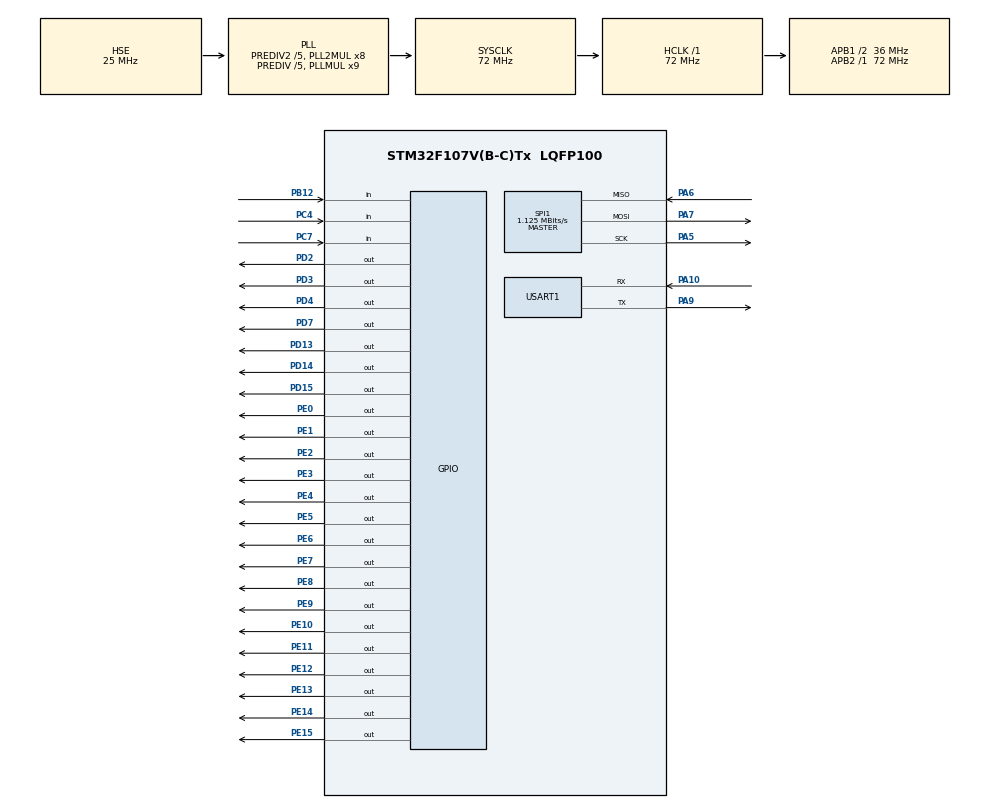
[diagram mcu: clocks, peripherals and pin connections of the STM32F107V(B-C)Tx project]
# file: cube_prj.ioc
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Dma.Request0=USART1_RX
Dma.Request1=USART1_TX
Dma.USART1_RX.0.Direction=DMA_PERIPH_TO_MEMORY
Dma.USART1_RX.0.Instance=DMA1_Channel5
Dma.USART1_RX.0.MemDataAlignment=DMA_MDATAALIGN_BYTE
Dma.USART1_RX.0.MemInc=DMA_MINC_DISABLE
Dma.USART1_RX.0.Mode=DMA_CIRCULAR
Dma.USART1_RX.0.PeriphDataAlignment=DMA_PDATAALIGN_BYTE
Dma.USART1_RX.0.PeriphInc=DMA_PINC_DISABLE
Dma.USART1_RX.0.Priority=DMA_PRIORITY_MEDIUM
Dma.USART1_TX.1.Direction=DMA_MEMORY_TO_PERIPH
Dma.USART1_TX.1.Instance=DMA1_Channel4
Dma.USART1_TX.1.MemDataAlignment=DMA_MDATAALIGN_BYTE
Dma.USART1_TX.1.MemInc=DMA_MINC_ENABLE
Dma.USART1_TX.1.Mode=DMA_NORMAL
Dma.USART1_TX.1.PeriphDataAlignment=DMA_PDATAALIGN_BYTE
Dma.USART1_TX.1.PeriphInc=DMA_PINC_DISABLE
Dma.USART1_TX.1.Priority=DMA_PRIORITY_MEDIUM
Mcu.Family=STM32F1
Mcu.Name=STM32F107V(B-C)Tx
Mcu.Package=LQFP100
NVIC.DMA1_Channel4_IRQn=true\:0\:0\:false\:false\:true
NVIC.DMA1_Channel5_IRQn=true\:0\:0\:false\:false\:true
NVIC.PriorityGroup=NVIC_PRIORITYGROUP_1
NVIC.USART1_IRQn=true\:0\:0\:false\:false\:true
OSC_IN.Mode=HSE-External-Oscillator
OSC_IN.Signal=RCC_OSC_IN
OSC_OUT.Mode=HSE-External-Oscillator
OSC_OUT.Signal=RCC_OSC_OUT
PA10.Mode=Asynchronous
PA10.Signal=USART1_RX
PA13.Mode=Serial_Wire
PA13.Signal=SYS_JTMS-SWDIO
PA14.Mode=Serial_Wire
PA14.Signal=SYS_JTCK-SWCLK
PA5.Mode=Full_Duplex_Master
PA5.Signal=SPI1_SCK
PA6.Mode=Full_Duplex_Master
PA6.Signal=SPI1_MISO
PA7.Mode=Full_Duplex_Master
PA7.Signal=SPI1_MOSI
PA9.Mode=Asynchronous
PA9.Signal=USART1_TX
PB12.Signal=GPIO_Input
PC14-OSC32_IN.Mode=LSE-External-Oscillator
PC14-OSC32_IN.Signal=RCC_OSC32_IN
PC15-OSC32_OUT.Mode=LSE-External-Oscillator
PC15-OSC32_OUT.Signal=RCC_OSC32_OUT
PC4.Signal=GPIO_Input
PC7.Signal=GPIO_Input
PD13.Signal=GPIO_Output
PD14.Signal=GPIO_Output
PD15.Signal=GPIO_Output
PD2.Signal=GPIO_Output
PD3.Signal=GPIO_Output
PD4.Signal=GPIO_Output
PD7.Signal=GPIO_Output
PE0.GPIO_Speed=GPIO_SPEED_HIGH
PE0.Signal=GPIO_Output
PE1.GPIO_Speed=GPIO_SPEED_HIGH
PE1.Signal=GPIO_Output
PE10.GPIO_Speed=GPIO_SPEED_HIGH
PE10.Signal=GPIO_Output
PE11.GPIO_Speed=GPIO_SPEED_HIGH
PE11.Signal=GPIO_Output
PE12.GPIO_Speed=GPIO_SPEED_HIGH
PE12.Signal=GPIO_Output
PE13.GPIO_Speed=GPIO_SPEED_HIGH
PE13.Signal=GPIO_Output
PE14.GPIO_Speed=GPIO_SPEED_HIGH
PE14.Signal=GPIO_Output
PE15.GPIO_Speed=GPIO_SPEED_HIGH
PE15.Signal=GPIO_Output
PE2.GPIO_Speed=GPIO_SPEED_HIGH
PE2.Signal=GPIO_Output
PE3.GPIO_Speed=GPIO_SPEED_HIGH
PE3.Signal=GPIO_Output
PE4.GPIO_Speed=GPIO_SPEED_HIGH
PE4.Signal=GPIO_Output
PE5.GPIO_Speed=GPIO_SPEED_HIGH
PE5.Signal=GPIO_Output
PE6.GPIO_Speed=GPIO_SPEED_HIGH
PE6.Signal=GPIO_Output
PE7.GPIO_Speed=GPIO_SPEED_HIGH
PE7.Signal=GPIO_Output
PE8.GPIO_Speed=GPIO_SPEED_HIGH
PE8.Signal=GPIO_Output
PE9.GPIO_Speed=GPIO_SPEED_HIGH
PE9.Signal=GPIO_Output
ProjectManager.HeapSize=0x400
ProjectManager.StackSize=0x200
ProjectManager.TargetToolchain=MDK-ARM V5
RCC.AHBFreq_Value=72000000
RCC.APB1CLKDivider=RCC_HCLK_DIV2
RCC.APB1Freq_Value=36000000
RCC.APB1TimFreq_Value=72000000
RCC.APB2Freq_Value=72000000
RCC.APB2TimFreq_Value=72000000
RCC.HCLKFreq_Value=72000000
RCC.HSEDivPLL=RCC_HSE_PREDIV_DIV5
RCC.HSE_VALUE=25000000
RCC.HSIState=RCC_HSI_ON
RCC.PLLMUL=RCC_PLL_MUL9
RCC.PLLSourceVirtual=RCC_PLLSOURCE_HSE
RCC.Prediv1Source=RCC_PREDIV1_SOURCE_PLL2
RCC.Prediv2=RCC_HSE_PREDIV2_DIV5
RCC.SYSCLKFreq_VALUE=72000000
RCC.SYSCLKSource=RCC_SYSCLKSOURCE_PLLCLK
RCC.USBFreq_Value=48000000
SPI1.BaudRatePrescaler=SPI_BAUDRATEPRESCALER_64
SPI1.CLKPhase=SPI_PHASE_2EDGE
SPI1.CLKPolarity=SPI_POLARITY_HIGH
SPI1.CalculateBaudRate=1.125 MBits/s
SPI1.Mode=SPI_MODE_MASTER
VP_CRC_VS_CRC.Mode=CRC_Activate
board=cube_prj

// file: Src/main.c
/**
  ******************************************************************************
  * File Name          : main.c
  * Description        : Main program body
  ******************************************************************************
  *
  * COPYRIGHT(c) 2016 STMicroelectronics
  *
  * Redistribution and use in source and binary forms, with or without modification,
  * are permitted provided that the following conditions are met:
  *   1. Redistributions of source code must retain the above copyright notice,
  *      this list of conditions and the following disclaimer.
  *   2. Redistributions in binary form must reproduce the above copyright notice,
  *      this list of conditions and the following disclaimer in the documentation
  *      and/or other materials provided with the distribution.
  *   3. Neither the name of STMicroelectronics nor the names of its contributors
  *      may be used to endorse or promote products derived from this software
  *      without specific prior written permission.
  *
  * THIS SOFTWARE IS PROVIDED BY THE COPYRIGHT HOLDERS AND CONTRIBUTORS "AS IS"
  * AND ANY EXPRESS OR IMPLIED WARRANTIES, INCLUDING, BUT NOT LIMITED TO, THE
  * IMPLIED WARRANTIES OF MERCHANTABILITY AND FITNESS FOR A PARTICULAR PURPOSE ARE
  * DISCLAIMED. IN NO EVENT SHALL THE COPYRIGHT HOLDER OR CONTRIBUTORS BE LIABLE
  * FOR ANY DIRECT, INDIRECT, INCIDENTAL, SPECIAL, EXEMPLARY, OR CONSEQUENTIAL
  * DAMAGES (INCLUDING, BUT NOT LIMITED TO, PROCUREMENT OF SUBSTITUTE GOODS OR
  * SERVICES; LOSS OF USE, DATA, OR PROFITS; OR BUSINESS INTERRUPTION) HOWEVER
  * CAUSED AND ON ANY THEORY OF LIABILITY, WHETHER IN CONTRACT, STRICT LIABILITY,
  * OR TORT (INCLUDING NEGLIGENCE OR OTHERWISE) ARISING IN ANY WAY OUT OF THE USE
  * OF THIS SOFTWARE, EVEN IF ADVISED OF THE POSSIBILITY OF SUCH DAMAGE.
  *
  ******************************************************************************
  */
#include "stm32f1xx_hal.h"
#include "crc.h"
#include "dma.h"
#include "spi.h"
#include "usart.h"
#include "gpio.h"

/* USER CODE BEGIN Includes */
#include "lcd_ssd1289.h"
#include "gui.h"            /**< STemwin */
#include "delay.h"
//#include "exti_dup.h"
//#include "tim_dup.h"
#include "uart_dup.h"
#include "led.h"
//#include "key.h"
//#include "app_led.h"
#include "ad7705.h"

/* USER CODE END Includes */

/* USER CODE BEGIN PV */
/* Private variables ---------------------------------------------------------*/

//#pragma diag_suppress 77,550,1294,1295
#pragma diag_suppress 870   /**< 排除非法字符串警�? */

/* USER CODE END PV */

void SystemClock_Config(void);

/* USER CODE BEGIN PFP */
/* Private function prototypes -----------------------------------------------*/

/* USER CODE END PFP */

/* USER CODE BEGIN 0 */
extern GUI_CONST_STORAGE GUI_FONT GUI_FontYaHei28;
//extern DMA_HandleTypeDef hdma_usart1_tx;
/* USER CODE END 0 */

int main(void)
{

  /* USER CODE BEGIN 1 */
//    uint16_t i = 0;
    uint16_t adc_value;

  /* USER CODE END 1 */

  /* MCU Configuration----------------------------------------------------------*/

  /* Reset of all peripherals, Initializes the Flash interface and the Systick. */
  HAL_Init();

  /* Configure the system clock */
  SystemClock_Config();

  /* Initialize all configured peripherals */
  MX_GPIO_Init();
  MX_DMA_Init();
  MX_CRC_Init();
  MX_USART1_UART_Init();
  MX_SPI1_Init();

  /* USER CODE BEGIN 2 */
    AD7705_init();

//    AD7705_self_calibration(1);
    adc_value = AD7705_get_adc_value(1);

//    GUI_Init();
//    GUI_UC_SetEncodeUTF8();
//
//    GUI_SetBkColor(GUI_BLACK);
//    GUI_SetColor(GUI_GREEN);
//
//    GUI_SetFont(&GUI_Font32B_ASCII);
//    GUI_DispStringAt("AD7705 Driver Test", 30, 50);

  /* USER CODE END 2 */

  /* Infinite loop */
  while (1)
  {

  /* USER CODE BEGIN 3 */
//    adc_value = AD7705_get_adc_value(1);
//
//    GUI_GotoXY(50, 100);
//    GUI_DispFloat((adc_value * 3300 / 65535), 4);
//    GUI_DispStringAt("mV", (50 + 70), 100);
  }
  /* USER CODE END 3 */

}

/** System Clock Configuration
*/
void SystemClock_Config(void)
{

  RCC_OscInitTypeDef RCC_OscInitStruct;
  RCC_ClkInitTypeDef RCC_ClkInitStruct;

  RCC_OscInitStruct.OscillatorType = RCC_OSCILLATORTYPE_HSE;
  RCC_OscInitStruct.HSEState = RCC_HSE_ON;
  RCC_OscInitStruct.HSEPredivValue = RCC_HSE_PREDIV_DIV5;
  RCC_OscInitStruct.Prediv1Source = RCC_PREDIV1_SOURCE_PLL2;
  RCC_OscInitStruct.PLL.PLLState = RCC_PLL_ON;
  RCC_OscInitStruct.PLL.PLLSource = RCC_PLLSOURCE_HSE;
  RCC_OscInitStruct.PLL.PLLMUL = RCC_PLL_MUL9;
  RCC_OscInitStruct.PLL2.PLL2State = RCC_PLL2_ON;
  RCC_OscInitStruct.PLL2.PLL2MUL = RCC_PLL2_MUL8;
  RCC_OscInitStruct.PLL2.HSEPrediv2Value = RCC_HSE_PREDIV2_DIV5;
  HAL_RCC_OscConfig(&RCC_OscInitStruct);

  RCC_ClkInitStruct.ClockType = RCC_CLOCKTYPE_HCLK|RCC_CLOCKTYPE_SYSCLK
                              |RCC_CLOCKTYPE_PCLK1|RCC_CLOCKTYPE_PCLK2;
  RCC_ClkInitStruct.SYSCLKSource = RCC_SYSCLKSOURCE_PLLCLK;
  RCC_ClkInitStruct.AHBCLKDivider = RCC_SYSCLK_DIV1;
  RCC_ClkInitStruct.APB1CLKDivider = RCC_HCLK_DIV2;
  RCC_ClkInitStruct.APB2CLKDivider = RCC_HCLK_DIV1;
  HAL_RCC_ClockConfig(&RCC_ClkInitStruct, FLASH_LATENCY_2);

  HAL_SYSTICK_Config(HAL_RCC_GetHCLKFreq()/1000);

  HAL_SYSTICK_CLKSourceConfig(SYSTICK_CLKSOURCE_HCLK);

  __HAL_RCC_PLLI2S_ENABLE();

  /* SysTick_IRQn interrupt configuration */
  HAL_NVIC_SetPriority(SysTick_IRQn, 0, 0);
}

/************************ (C) COPYRIGHT STMicroelectronics *****END OF FILE****/
